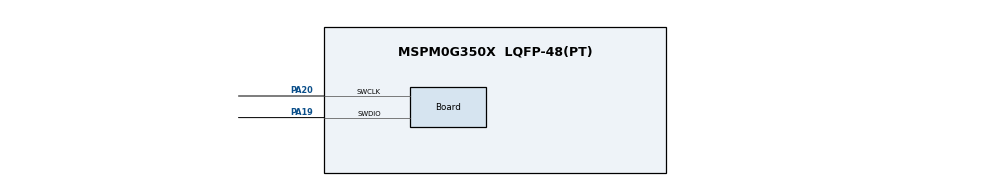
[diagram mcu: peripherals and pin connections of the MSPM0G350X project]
/**
 * @cliArgs --device "MSPM0G350X" --part "Default" --package "LQFP-48(PT)" --product "mspm0_sdk@2.04.00.06"
 * @versions {"tool":"1.23.0+4000"}
 */

/**
 * Import the modules used in this configuration.
 */
const ADC12         = scripting.addModule("/ti/driverlib/ADC12", {}, false);
const ADC121        = ADC12.addInstance();
const SYSCTL        = scripting.addModule("/ti/driverlib/SYSCTL");
const TIMER         = scripting.addModule("/ti/driverlib/TIMER", {}, false);
const TIMER1        = TIMER.addInstance();
const ProjectConfig = scripting.addModule("/ti/project_config/ProjectConfig");

/**
 * Write custom configuration values to the imported modules.
 */
ADC121.$name                             = "ADC12_0";
ADC121.powerDownMode                     = "DL_ADC12_POWER_DOWN_MODE_MANUAL";
ADC121.sampleTime0                       = "62.5ns";
ADC121.enabledInterrupts                 = ["DL_ADC12_INTERRUPT_DMA_DONE"];
ADC121.configureDMA                      = true;
ADC121.repeatMode                        = true;
ADC121.trigSrc                           = "DL_ADC12_TRIG_SRC_EVENT";
ADC121.subChanID                         = 1;
ADC121.adcMem0trig                       = "DL_ADC12_TRIGGER_MODE_TRIGGER_NEXT";
ADC121.sampCnt                           = 1;
ADC121.enabledDMATriggers                = ["DL_ADC12_DMA_MEM0_RESULT_LOADED"];
ADC121.peripheral.$assign                = "ADC0";
ADC121.adcPin0Config.$name               = "ti_driverlib_gpio_GPIOPinGeneric0";
ADC121.DMA_CHANNEL.$name                 = "DMA_CH0";
ADC121.DMA_CHANNEL.addressMode           = "f2b";
ADC121.DMA_CHANNEL.configureTransferSize = true;
ADC121.DMA_CHANNEL.transferMode          = "FULL_CH_REPEAT_SINGLE";
ADC121.DMA_CHANNEL.srcLength             = "HALF_WORD";
ADC121.DMA_CHANNEL.dstLength             = "HALF_WORD";
ADC121.DMA_CHANNEL.transferSize          = 1024;
ADC121.DMA_CHANNEL.peripheral.$assign    = "DMA_CH0";

const Board                       = scripting.addModule("/ti/driverlib/Board", {}, false);
Board.peripheral.$assign          = "DEBUGSS";
Board.peripheral.swclkPin.$assign = "PA20";
Board.peripheral.swdioPin.$assign = "PA19";

SYSCTL.peripheral.$assign = "SYSCTL";

TIMER1.$name                       = "TIMER_0";
TIMER1.timerMode                   = "PERIODIC";
TIMER1.event1PublisherChannel      = 1;
TIMER1.timerPeriod                 = "1us";
TIMER1.event1ControllerInterruptEn = ["ZERO_EVENT"];
TIMER1.peripheral.$assign          = "TIMA0";

ProjectConfig.migrationCondition = true;
ProjectConfig.genLibCMSIS        = true;

/**
 * Pinmux solution for unlocked pins/peripherals. This ensures that minor changes to the automatic solver in a future
 * version of the tool will not impact the pinmux you originally saw.  These lines can be completely deleted in order to
 * re-solve from scratch.
 */
ADC121.peripheral.adcPin0.$suggestSolution = "PA27";
